AUTOSAR XML (schema 4-0-3)
package /ComponentTypes
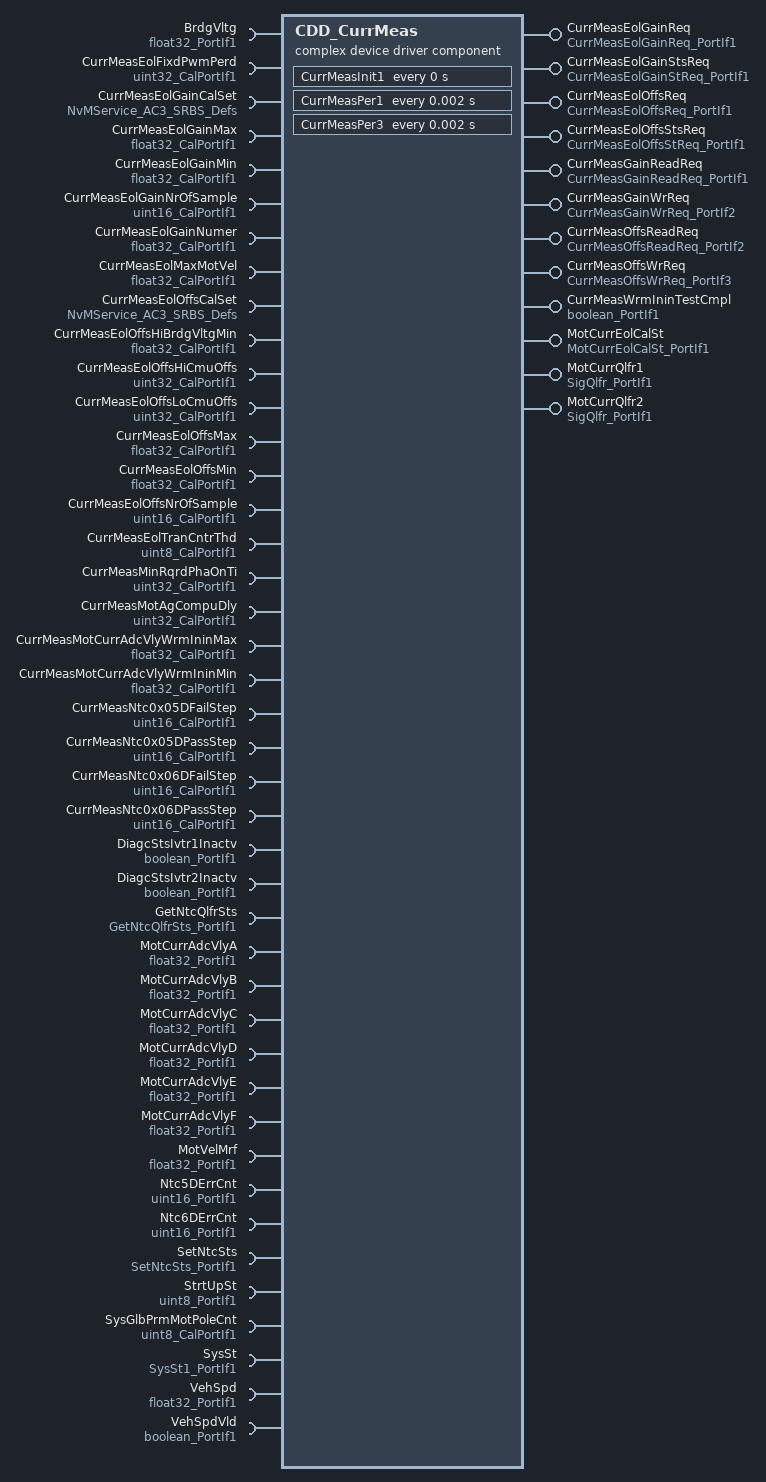
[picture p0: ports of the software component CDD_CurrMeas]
  complex device driver sw component type CDD_CurrMeas
    12 x provide port:
      CurrMeasEolGainReq: server-com-spec{operation=Oper, queue-length=1}, provided-interface=CurrMeasEolGainReq_PortIf1
      CurrMeasEolGainStsReq: server-com-spec{operation=Oper, queue-length=1}, provided-interface=CurrMeasEolGainStReq_PortIf1
      CurrMeasEolOffsReq: server-com-spec{operation=Oper, queue-length=1}, provided-interface=CurrMeasEolOffsReq_PortIf1
      CurrMeasEolOffsStsReq: server-com-spec{operation=Oper, queue-length=1}, provided-interface=CurrMeasEolOffsStReq_PortIf1
      CurrMeasGainReadReq: server-com-spec{operation=Oper, queue-length=1}, provided-interface=CurrMeasGainReadReq_PortIf1
      CurrMeasGainWrReq: server-com-spec{operation=Oper, queue-length=1}, provided-interface=CurrMeasGainWrReq_PortIf2
      CurrMeasOffsReadReq: server-com-spec{operation=Oper, queue-length=1}, provided-interface=CurrMeasOffsReadReq_PortIf2
      CurrMeasOffsWrReq: server-com-spec{operation=Oper, queue-length=1}, provided-interface=CurrMeasOffsWrReq_PortIf3
      CurrMeasWrmIninTestCmpl: nonqueued-sender-com-spec{data-element=Logl, init-value=0}, provided-interface=boolean_PortIf1
      MotCurrEolCalSt: nonqueued-sender-com-spec{data-element=Val, init-value=0}, provided-interface=MotCurrEolCalSt_PortIf1
      MotCurrQlfr1: nonqueued-sender-com-spec{data-element=Val, init-value=0}, provided-interface=SigQlfr_PortIf1
      MotCurrQlfr2: nonqueued-sender-com-spec{data-element=Val, init-value=0}, provided-interface=SigQlfr_PortIf1
    42 x require port:
      BrdgVltg: nonqueued-receiver-com-spec{data-element=Val, filter=data-filter-type=ALWAYS, init-value=6}, required-interface=float32_PortIf1
      CurrMeasEolFixdPwmPerd: parameter-require-com-spec{init-value=62500, parameter=Val}, required-interface=uint32_CalPortIf1
      CurrMeasEolGainCalSet: required-interface=NvMService_AC3_SRBS_Defs
      CurrMeasEolGainMax: parameter-require-com-spec{init-value=76, parameter=Val}, required-interface=float32_CalPortIf1
      CurrMeasEolGainMin: parameter-require-com-spec{init-value=56, parameter=Val}, required-interface=float32_CalPortIf1
      CurrMeasEolGainNrOfSample: parameter-require-com-spec{init-value=5, parameter=Val}, required-interface=uint16_CalPortIf1
      CurrMeasEolGainNumer: parameter-require-com-spec{init-value=45, parameter=Val}, required-interface=float32_CalPortIf1
      CurrMeasEolMaxMotVel: parameter-require-com-spec{init-value=16, parameter=Val}, required-interface=float32_CalPortIf1
      CurrMeasEolOffsCalSet: required-interface=NvMService_AC3_SRBS_Defs
      CurrMeasEolOffsHiBrdgVltgMin: parameter-require-com-spec{init-value=262500, parameter=Val}, required-interface=float32_CalPortIf1
      CurrMeasEolOffsHiCmuOffs: parameter-require-com-spec{init-value=50000, parameter=Val}, required-interface=uint32_CalPortIf1
      CurrMeasEolOffsLoCmuOffs: parameter-require-com-spec{init-value=6250, parameter=Val}, required-interface=uint32_CalPortIf1
      CurrMeasEolOffsMax: parameter-require-com-spec{init-value=2.8, parameter=Val}, required-interface=float32_CalPortIf1
      CurrMeasEolOffsMin: parameter-require-com-spec{init-value=2.3, parameter=Val}, required-interface=float32_CalPortIf1
      CurrMeasEolOffsNrOfSample: parameter-require-com-spec{init-value=20, parameter=Val}, required-interface=uint16_CalPortIf1
      CurrMeasEolTranCntrThd: parameter-require-com-spec{init-value=5, parameter=Val}, required-interface=uint8_CalPortIf1
      CurrMeasMinRqrdPhaOnTi: parameter-require-com-spec{init-value=11000, parameter=Val}, required-interface=uint32_CalPortIf1
      CurrMeasMotAgCompuDly: parameter-require-com-spec{init-value=30000, parameter=Val}, required-interface=uint32_CalPortIf1
      CurrMeasMotCurrAdcVlyWrmIninMax: parameter-require-com-spec{init-value=3, parameter=Val}, required-interface=float32_CalPortIf1
      CurrMeasMotCurrAdcVlyWrmIninMin: parameter-require-com-spec{init-value=2.0, parameter=Val}, required-interface=float32_CalPortIf1
      CurrMeasNtc0x05DFailStep: parameter-require-com-spec{init-value=16384, parameter=Val}, required-interface=uint16_CalPortIf1
      CurrMeasNtc0x05DPassStep: parameter-require-com-spec{init-value=16384, parameter=Val}, required-interface=uint16_CalPortIf1
      CurrMeasNtc0x06DFailStep: parameter-require-com-spec{init-value=16384, parameter=Val}, required-interface=uint16_CalPortIf1
      CurrMeasNtc0x06DPassStep: parameter-require-com-spec{init-value=16384, parameter=Val}, required-interface=uint16_CalPortIf1
      DiagcStsIvtr1Inactv: nonqueued-receiver-com-spec{data-element=Logl, filter=data-filter-type=ALWAYS, init-value=0}, required-interface=boolean_PortIf1
      DiagcStsIvtr2Inactv: nonqueued-receiver-com-spec{data-element=Logl, filter=data-filter-type=ALWAYS, init-value=0}, required-interface=boolean_PortIf1
      GetNtcQlfrSts: required-interface=GetNtcQlfrSts_PortIf1
      MotCurrAdcVlyA: nonqueued-receiver-com-spec{data-element=Val, filter=data-filter-type=ALWAYS, init-value=0}, required-interface=float32_PortIf1
      MotCurrAdcVlyB: nonqueued-receiver-com-spec{data-element=Val, filter=data-filter-type=ALWAYS, init-value=0}, required-interface=float32_PortIf1
      MotCurrAdcVlyC: nonqueued-receiver-com-spec{data-element=Val, filter=data-filter-type=ALWAYS, init-value=0}, required-interface=float32_PortIf1
      MotCurrAdcVlyD: nonqueued-receiver-com-spec{data-element=Val, filter=data-filter-type=ALWAYS, init-value=0}, required-interface=float32_PortIf1
      MotCurrAdcVlyE: nonqueued-receiver-com-spec{data-element=Val, filter=data-filter-type=ALWAYS, init-value=0}, required-interface=float32_PortIf1
      MotCurrAdcVlyF: nonqueued-receiver-com-spec{data-element=Val, filter=data-filter-type=ALWAYS, init-value=0}, required-interface=float32_PortIf1
      MotVelMrf: nonqueued-receiver-com-spec{data-element=Val, filter=data-filter-type=ALWAYS, init-value=0}, required-interface=float32_PortIf1
      Ntc5DErrCnt: nonqueued-receiver-com-spec{data-element=Val, filter=data-filter-type=ALWAYS, init-value=0}, required-interface=uint16_PortIf1
      Ntc6DErrCnt: nonqueued-receiver-com-spec{data-element=Val, filter=data-filter-type=ALWAYS, init-value=0}, required-interface=uint16_PortIf1
      SetNtcSts: required-interface=SetNtcSts_PortIf1
      StrtUpSt: nonqueued-receiver-com-spec{data-element=Val, filter=data-filter-type=ALWAYS, init-value=0}, required-interface=uint8_PortIf1
      SysGlbPrmMotPoleCnt: parameter-require-com-spec{init-value=6, parameter=Val}, required-interface=uint8_CalPortIf1
      SysSt: nonqueued-receiver-com-spec{data-element=Val, filter=data-filter-type=ALWAYS, init-value=3}, required-interface=SysSt1_PortIf1
      VehSpd: nonqueued-receiver-com-spec{data-element=Val, filter=data-filter-type=ALWAYS, init-value=0.0}, required-interface=float32_PortIf1
      VehSpdVld: nonqueued-receiver-com-spec{data-element=Logl, filter=data-filter-type=ALWAYS, init-value=0}, required-interface=boolean_PortIf1
    behavior CDD_CurrMeas_InternalBehavior: data-type-mapping=Nexteer
      ar-typed-per-instance-memorys:
        57 x data, all with sw-calibration-access=READ-ONLY:
          BrdgVltgSumPrev: type=float32
          CurrMeasEolGainCalSet: type=CurrMeasEolGainCalRec1
          CurrMeasEolOffsCalSet: type=CurrMeasEolOffsCalRec1
          EolGainSts: type=uint8
          EolOffsHiBrdgVltg: type=float32
          EolOffsSts: type=uint8
          EolTranCntrPrev: type=uint8
          GainEolAvrgCntrPrev: type=uint16
          MotCtrlNtc5DErrCntPrev: type=uint16
          MotCtrlNtc6DErrCntPrev: type=uint16
          MotCurrEolCalStPrev: type=MotCurrEolCalSt2
          MotCurrEolGainA: type=float32
          MotCurrEolGainB: type=float32
          MotCurrEolGainC: type=float32
          MotCurrEolGainD: type=float32
          MotCurrEolGainE: type=float32
          MotCurrEolGainF: type=float32
          MotCurrEolOffsProcFlg: type=boolean
          MotCurrOffsDeltaA: type=float32
          MotCurrOffsDeltaB: type=float32
          MotCurrOffsDeltaC: type=float32
          MotCurrOffsDeltaD: type=float32
          MotCurrOffsDeltaE: type=float32
          MotCurrOffsDeltaF: type=float32
          MotCurrOffsHiAvrgA: type=float32
          MotCurrOffsHiAvrgB: type=float32
          MotCurrOffsHiAvrgC: type=float32
          MotCurrOffsHiAvrgD: type=float32
          MotCurrOffsHiAvrgE: type=float32
          MotCurrOffsHiAvrgF: type=float32
          MotCurrOffsLoAvrgA: type=float32
          MotCurrOffsLoAvrgB: type=float32
          MotCurrOffsLoAvrgC: type=float32
          MotCurrOffsLoAvrgD: type=float32
          MotCurrOffsLoAvrgE: type=float32
          MotCurrOffsLoAvrgF: type=float32
          MotCurrOffsZeroAvrgA: type=float32
          MotCurrOffsZeroAvrgB: type=float32
          MotCurrOffsZeroAvrgC: type=float32
          MotCurrOffsZeroAvrgD: type=float32
          MotCurrOffsZeroAvrgE: type=float32
          MotCurrOffsZeroAvrgF: type=float32
          MotCurrRollgCnt1Prev: type=uint8
          MotCurrRollgCnt2Prev: type=uint8
          MotCurrSumAPrev: type=float32
          MotCurrSumBPrev: type=float32
          MotCurrSumCPrev: type=float32
          MotCurrSumDPrev: type=float32
          MotCurrSumEPrev: type=float32
          MotCurrSumFPrev: type=float32
          Ntc5DErrCnt2MilliSecPrev: type=uint16
          Ntc6DErrCnt2MilliSecPrev: type=uint16
          OffsEolAvrgCntrPrev: type=uint16
          PhaOnTiErrCntPrev: type=uint16
          TempMotCurrAdcVlySum1Prev: type=float32
          TempMotCurrAdcVlySum2Prev: type=float32
          WrmIninTestCmplPrev: type=boolean
      6 x operation invoked event:
        OIT_CurrMeasEolGainReq_Oper_CurrMeasEolGainReq_Oper: start-on-event=CurrMeasEolGainReq_Oper, operation=CurrMeasEolGainReq.Oper
        OIT_CurrMeasEolGainStsReq_Oper_CurrMeasEolGainStsReq_Oper: start-on-event=CurrMeasEolGainStsReq_Oper, operation=CurrMeasEolGainStsReq.Oper
        OIT_CurrMeasEolOffsReq_Oper_CurrMeasEolOffsReq_Oper: start-on-event=CurrMeasEolOffsReq_Oper, operation=CurrMeasEolOffsReq.Oper
        OIT_CurrMeasEolOffsStsReq_Oper_CurrMeasEolOffsStsReq_Oper: start-on-event=CurrMeasEolOffsStsReq_Oper, operation=CurrMeasEolOffsStsReq.Oper
        OIT_CurrMeasGainReadReq_Oper_CurrMeasGainReadReq_Oper: start-on-event=CurrMeasGainReadReq_Oper, operation=CurrMeasGainReadReq.Oper
        OIT_CurrMeasGainWrReq_Oper_CurrMeasGainWrReq_Oper: start-on-event=CurrMeasGainWrReq_Oper, operation=CurrMeasGainWrReq.Oper
      timing event CurrMeasInit1_InitEvent: start-on-event=CurrMeasInit1, period=0
      operation invoked event OIT_CurrMeasOffsReadReq_Oper_CurrMeasOffsReadReq_Oper: start-on-event=CurrMeasOffsReadReq_Oper, operation=CurrMeasOffsReadReq.Oper
      operation invoked event OIT_CurrMeasOffsWrReq_Oper_CurrMeasOffsWrReq_Oper: start-on-event=CurrMeasOffsWrReq_Oper, operation=CurrMeasOffsWrReq.Oper
      timing event TMT_CurrMeasPer1: start-on-event=CurrMeasPer1, period=0.002
      timing event TMT_CurrMeasPer3: start-on-event=CurrMeasPer3, period=0.002
      11 x runnable:
        CurrMeasEolGainReq_Oper
        CurrMeasEolGainStsReq_Oper
        CurrMeasEolOffsReq_Oper
        CurrMeasEolOffsStsReq_Oper
        CurrMeasGainReadReq_Oper
        CurrMeasGainWrReq_Oper
          sync call SC_CurrMeasEolGainCalSet_SetRamBlockStatus: operation=CurrMeasEolGainCalSet.SetRamBlockStatus, timeout=0
        CurrMeasInit1
        CurrMeasOffsReadReq_Oper
        CurrMeasOffsWrReq_Oper
          sync call SC_CurrMeasEolOffsCalSet_SetRamBlockStatus: operation=CurrMeasEolOffsCalSet.SetRamBlockStatus, timeout=0
        CurrMeasPer1
          data-receive-point-by-arguments:
            12 x access:
              REC_BrdgVltg_Val: accessed-variable=BrdgVltg.Val
              REC_DiagcStsIvtr1Inactv_Logl: accessed-variable=DiagcStsIvtr1Inactv.Logl
              REC_DiagcStsIvtr2Inactv_Logl: accessed-variable=DiagcStsIvtr2Inactv.Logl
              REC_MotCurrAdcVlyA_Val: accessed-variable=MotCurrAdcVlyA.Val
              REC_MotCurrAdcVlyB_Val: accessed-variable=MotCurrAdcVlyB.Val
              REC_MotCurrAdcVlyC_Val: accessed-variable=MotCurrAdcVlyC.Val
              REC_MotCurrAdcVlyD_Val: accessed-variable=MotCurrAdcVlyD.Val
              REC_MotCurrAdcVlyE_Val: accessed-variable=MotCurrAdcVlyE.Val
              REC_MotCurrAdcVlyF_Val: accessed-variable=MotCurrAdcVlyF.Val
              REC_MotVelMrf_Val: accessed-variable=MotVelMrf.Val
              REC_VehSpd_Val: accessed-variable=VehSpd.Val
              REC_VehSpdVld_Logl: accessed-variable=VehSpdVld.Logl
          data-send-points:
            access SEND_MotCurrEolCalSt_Val: accessed-variable=MotCurrEolCalSt.Val
          sync call SC_CurrMeasEolGainCalSet_SetRamBlockStatus: operation=CurrMeasEolGainCalSet.SetRamBlockStatus, timeout=0
          sync call SC_CurrMeasEolOffsCalSet_SetRamBlockStatus: operation=CurrMeasEolOffsCalSet.SetRamBlockStatus, timeout=0
          sync call SC_SetNtcSts_Oper: operation=SetNtcSts.Oper, timeout=0
        CurrMeasPer3
          data-receive-point-by-arguments:
            12 x access:
              REC_DiagcStsIvtr1Inactv_Logl: accessed-variable=DiagcStsIvtr1Inactv.Logl
              REC_DiagcStsIvtr2Inactv_Logl: accessed-variable=DiagcStsIvtr2Inactv.Logl
              REC_MotCurrAdcVlyA_Val: accessed-variable=MotCurrAdcVlyA.Val
              REC_MotCurrAdcVlyB_Val: accessed-variable=MotCurrAdcVlyB.Val
              REC_MotCurrAdcVlyC_Val: accessed-variable=MotCurrAdcVlyC.Val
              REC_MotCurrAdcVlyD_Val: accessed-variable=MotCurrAdcVlyD.Val
              REC_MotCurrAdcVlyE_Val: accessed-variable=MotCurrAdcVlyE.Val
              REC_MotCurrAdcVlyF_Val: accessed-variable=MotCurrAdcVlyF.Val
              REC_Ntc5DErrCnt_Val: accessed-variable=Ntc5DErrCnt.Val
              REC_Ntc6DErrCnt_Val: accessed-variable=Ntc6DErrCnt.Val
              REC_StrtUpSt_Val: accessed-variable=StrtUpSt.Val
              REC_SysSt_Val: accessed-variable=SysSt.Val
          data-send-points:
            access SEND_CurrMeasWrmIninTestCmpl_Logl: accessed-variable=CurrMeasWrmIninTestCmpl.Logl
            access SEND_MotCurrQlfr1_Val: accessed-variable=MotCurrQlfr1.Val
            access SEND_MotCurrQlfr2_Val: accessed-variable=MotCurrQlfr2.Val
          sync call SC_GetNtcQlfrSts_Oper: operation=GetNtcQlfrSts.Oper, timeout=0
          sync call SC_SetNtcSts_Oper: operation=SetNtcSts.Oper, timeout=0
      swc service dependency NvmCurrMeasEolGainCalSet
        assigned-datas:
          role=ramBlock, used-data-element=CurrMeasEolGainCalSet
          role=defaultValue, used-parameter-element=CurrMeasEolGainCalSetDft
        assigned-ports:
          port-prototype=CurrMeasEolGainCalSet, role=NvMService_AC3_SRBS_Defs
          port-prototype=CurrMeasEolGainCalSet, role=NvMService_AC3_SRBS_Defs
        service-needs:
          nv block needs NvmCurrMeasEolGainCalSet: n-data-sets=0, readonly=false, reliability=ERROR-DETECTION, resistant-to-changed-sw=true, restore-at-start=true, store-at-shutdown=true, write-only-once=false, writing-frequency=0, writing-priority=LOW
      swc service dependency NvmCurrMeasEolOffsCalSet
        assigned-datas:
          role=ramBlock, used-data-element=CurrMeasEolOffsCalSet
          role=defaultValue, used-parameter-element=CurrMeasEolOffsCalSetDft
        assigned-ports:
          port-prototype=CurrMeasEolOffsCalSet, role=NvMService_AC3_SRBS_Defs
          port-prototype=CurrMeasEolOffsCalSet, role=NvMService_AC3_SRBS_Defs
        service-needs:
          nv block needs NvmCurrMeasEolOffsCalSet: n-data-sets=0, readonly=false, reliability=ERROR-DETECTION, resistant-to-changed-sw=true, restore-at-start=true, store-at-shutdown=true, write-only-once=false, writing-frequency=0, writing-priority=LOW
      shared-parameters:
        parameter data prototype CurrMeasEolGainCalSetDft: sw-calibration-access=READ-WRITE, type=CurrMeasEolGainCalRec1, init-value=fields=[CurrMeasMotCurrEolGainA:66.6, CurrMeasMotCurrEolGainB:66.6, CurrMeasMotCurrEolGainC:66.6, CurrMeasMotCurrEolGainD:66.6, CurrMeasMotCurrEolGainE:66.6, CurrMeasMotCurrEolGainF:66.6]
        parameter data prototype CurrMeasEolOffsCalSetDft:
          sw-calibration-access=READ-WRITE
          type=CurrMeasEolOffsCalRec1
          init-value=fields=[CurrMeasEolOffsHiBrdgVltg:700000, CurrMeasMotCurrEolOffsDifA:0, CurrMeasMotCurrEolOffsDifB:0, CurrMeasMotCurrEolOffsDifC:0, CurrMeasMotCurrEolOffsDifD:0, CurrMeasMotCurrEolOffsDifE:0, CurrMeasMotCurrEolOffsDifF:0, CurrMeasMotCurrOffsLoAvrgA:2.5, CurrMeasMotCurrOffsLoAvrgB:2.5, CurrMeasMotCurrOffsLoAvrgC:2.5, CurrMeasMotCurrOffsLoAvrgD:2.5, CurrMeasMotCurrOffsLoAvrgE:2.5, CurrMeasMotCurrOffsLoAvrgF:2.5]
  swc implementation CDD_CurrMeas_Implementation: behavior=CDD_CurrMeas_InternalBehavior
    code-descriptors:
      code Default: artifact-descriptors=autosar-engineering-object={short-label=Default, category=SWSRC}
